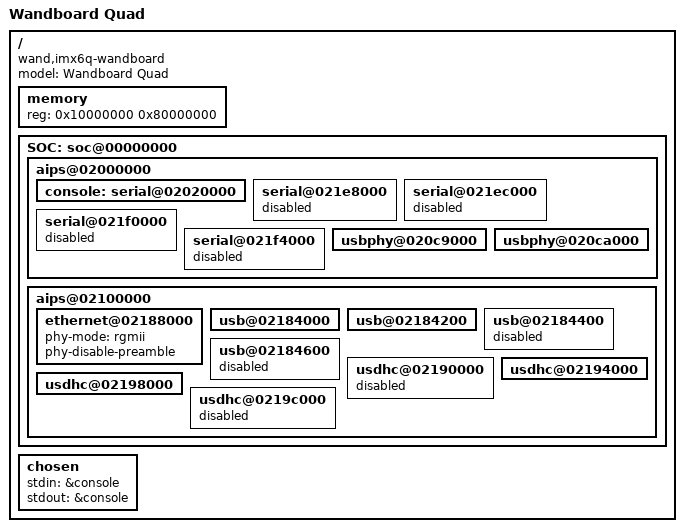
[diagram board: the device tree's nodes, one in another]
/*
 * Copyright (c) 2013 Ian Lepore
 * All rights reserved.
 *
 * Redistribution and use in source and binary forms, with or without
 * modification, are permitted provided that the following conditions
 * are met:
 * 1. Redistributions of source code must retain the above copyright
 *    notice, this list of conditions and the following disclaimer.
 * 2. Redistributions in binary form must reproduce the above copyright
 *    notice, this list of conditions and the following disclaimer in the
 *    documentation and/or other materials provided with the distribution.
 *
 * THIS SOFTWARE IS PROVIDED BY THE AUTHOR AND CONTRIBUTORS ``AS IS'' AND
 * ANY EXPRESS OR IMPLIED WARRANTIES, INCLUDING, BUT NOT LIMITED TO, THE
 * IMPLIED WARRANTIES OF MERCHANTABILITY AND FITNESS FOR A PARTICULAR PURPOSE
 * ARE DISCLAIMED. IN NO EVENT SHALL THE AUTHOR OR CONTRIBUTORS BE LIABLE
 * FOR ANY DIRECT, INDIRECT, INCIDENTAL, SPECIAL, EXEMPLARY, OR CONSEQUENTIAL
 * DAMAGES (INCLUDING, BUT NOT LIMITED TO, PROCUREMENT OF SUBSTITUTE GOODS
 * OR SERVICES; LOSS OF USE, DATA, OR PROFITS; OR BUSINESS INTERRUPTION)
 * HOWEVER CAUSED AND ON ANY THEORY OF LIABILITY, WHETHER IN CONTRACT, STRICT
 * LIABILITY, OR TORT (INCLUDING NEGLIGENCE OR OTHERWISE) ARISING IN ANY WAY
 * OUT OF THE USE OF THIS SOFTWARE, EVEN IF ADVISED OF THE POSSIBILITY OF
 * SUCH DAMAGE.
 *
 * Wandboard Quad.
 *
 * $FreeBSD$
 */

/dts-v1/;
/include/ "imx6.dtsi"

/ {
	#address-cells = <1>;
	#size-cells = <1>;

	model = "Wandboard Quad";
	compatible = "wand,imx6q-wandboard", "fsl,imx6q";

	memory {
		reg = <0x10000000 0x80000000>; /* RAM 2GB */
	};

	SOC: soc@00000000 {
		aips@02000000 { /* AIPS1 */
//			iomux@73fa8000		{ status = "disabled"; };
//			gpio@0209C000		{ status = "disabled"; };
//			gpio@020A0000		{ status = "disabled"; };
//			gpio@020A4000		{ status = "disabled"; };
//			gpio@020A8000		{ status = "disabled"; };
			console:serial@02020000 { status = "okay"; };
			serial@021e8000		{ status = "disabled"; };
			serial@021ec000		{ status = "disabled"; };
			serial@021f0000		{ status = "disabled"; };
			serial@021f4000		{ status = "disabled"; };
			usbphy@020c9000		{ status = "okay"; };
			usbphy@020ca000		{ status = "okay"; };
		};
		aips@02100000 { /* AIPS2 */
			ethernet@02188000	{ 
				status = "okay";
				phy-mode = "rgmii";
				phy-disable-preamble;
			};
			usb@02184000		{ status = "okay"; };
			usb@02184200		{ status = "okay"; };
			usb@02184400		{ status = "disabled"; };
			usb@02184600		{ status = "disabled"; };
			usdhc@02190000		{ status = "disabled"; };
			usdhc@02194000		{ status = "okay"; };
			usdhc@02198000		{ status = "okay"; };
			usdhc@0219c000		{ status = "disabled"; };
		};
	};

	chosen {
		stdin = &console;
		stdout = &console;
	};
};
